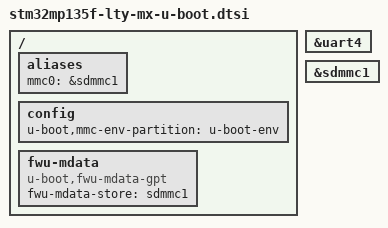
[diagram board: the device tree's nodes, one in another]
// SPDX-License-Identifier: (GPL-2.0-or-later OR BSD-3-Clause)
/*
 * Copyright (C) 2026, STMicroelectronics - All Rights Reserved
 * Author: STM32CubeMX code generation for STMicroelectronics.
 */

/* For more information on Device Tree configuration, please refer to
 * https://wiki.st.com/stm32mpu/wiki/Category:Device_tree_configuration
 */

/* USER CODE BEGIN includes */
#include "stm32mp13-u-boot.dtsi"
/* USER CODE END includes */

/ {

	/* USER CODE BEGIN root */
	aliases {
		mmc0 = &sdmmc1;
	};
	config {
		u-boot,mmc-env-partition = "u-boot-env";
	};
	
	fwu-mdata{
		compatible = "u-boot,fwu-mdata-gpt";
		fwu-mdata-store = <&sdmmc1>;
	};
	/* USER CODE END root */

}; /*root*/

/* USER CODE BEGIN addons */

&uart4 {
    bootph-all;
};

&sdmmc1 {
    bootph-all;
};

/* USER CODE END addons */

